AUTOSAR XML (schema 321)
package /ComponentType
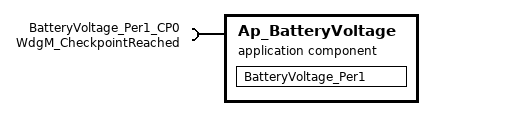
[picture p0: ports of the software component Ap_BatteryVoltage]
  application software component type Ap_BatteryVoltage
    require port BatteryVoltage_Per1_CP0: client-com-spec=CheckpointReached, required-interface=WdgM_CheckpointReached
  internal behavior Ap_BatteryVoltage_InternalBehavior: component=Ap_BatteryVoltage, port-api-option{enable-take-address=false, indirect-api=false, port=BatteryVoltage_Per1_CP0}
    runnable BatteryVoltage_Per1
      sync call SC_BatteryVoltage_Per1_CP0_CheckpointReached: operation=BatteryVoltage_Per1_CP0.CheckpointReached, timeout=0
  swc implementation Ap_BatteryVoltage_Implementation: behavior=Ap_BatteryVoltage_InternalBehavior
    code-descriptors:
      code Code: type=SRC
package /PortInterface
  client server interface WdgM_CheckpointReached: is-service=true
    operation CheckpointReached: possible-error=E_NOT_OK  # Indicates to the Watchdog Manager that a Checkpoint within a Supervised Entity has been reached.
    error E_NOT_OK: error-code=1
